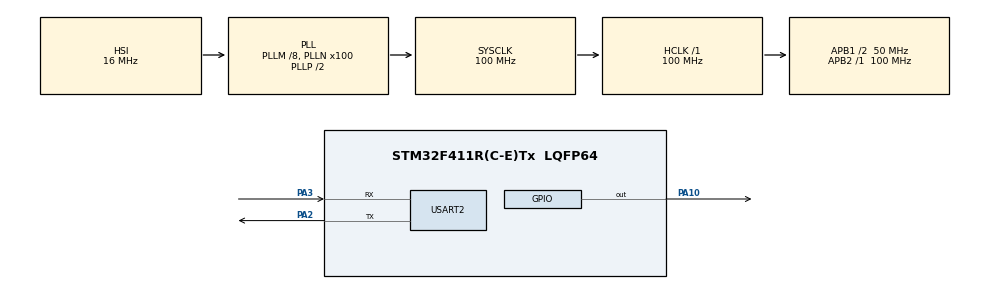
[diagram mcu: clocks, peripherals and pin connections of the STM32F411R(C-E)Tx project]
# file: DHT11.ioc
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Mcu.Family=STM32F4
Mcu.Name=STM32F411R(C-E)Tx
Mcu.Package=LQFP64
NVIC.PriorityGroup=NVIC_PRIORITYGROUP_4
PA10.Signal=GPIO_Output
PA2.Mode=Asynchronous
PA2.Signal=USART2_TX
PA3.Mode=Asynchronous
PA3.Signal=USART2_RX
ProjectManager.HeapSize=0x200
ProjectManager.StackSize=0x400
ProjectManager.TargetToolchain=STM32CubeIDE
RCC.48MHZClocksFreq_Value=50000000
RCC.AHBFreq_Value=100000000
RCC.APB1CLKDivider=RCC_HCLK_DIV2
RCC.APB1Freq_Value=50000000
RCC.APB1TimFreq_Value=100000000
RCC.APB2Freq_Value=100000000
RCC.APB2TimFreq_Value=100000000
RCC.CortexFreq_Value=100000000
RCC.HCLKFreq_Value=100000000
RCC.HSE_VALUE=25000000
RCC.HSI_VALUE=16000000
RCC.LSE_VALUE=32768
RCC.PLLM=8
RCC.PLLN=100
RCC.SYSCLKFreq_VALUE=100000000
RCC.SYSCLKSource=RCC_SYSCLKSOURCE_PLLCLK
RCC.VCOOutputFreq_Value=200000000
TIM1.Period=0xffff-1
TIM1.Prescaler=100-1
USART2.VirtualMode=VM_ASYNC
VP_TIM1_VS_ClockSourceINT.Mode=Internal
board=custom

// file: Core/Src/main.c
/* USER CODE BEGIN Header */
/**
  ******************************************************************************
  * @file           : main.c
  * @brief          : Main program body
  ******************************************************************************
  * @attention
  *
  * Copyright (c) 2023 STMicroelectronics.
  * All rights reserved.
  *
  * This software is licensed under terms that can be found in the LICENSE file
  * in the root directory of this software component.
  * If no LICENSE file comes with this software, it is provided AS-IS.
  *
  ******************************************************************************
  */
/* USER CODE END Header */
#include "main.h"
#include "tim.h"
#include "usart.h"
#include "gpio.h"

/* USER CODE BEGIN Includes */
#include "stdlib.h"
#include "string.h"
/* USER CODE END Includes */

/* USER CODE BEGIN PV */
uint8_t threshold = 50;
uint8_t RH_int;
uint8_t RH_dec;
uint8_t T_int;
uint8_t T_dec;
uint8_t checksum;
/* USER CODE END PV */

void SystemClock_Config(void);

/* USER CODE BEGIN 0 */
void HAL_DelayUs(uint16_t us)
{
	__HAL_TIM_SET_COUNTER(&htim1,0);
	while(__HAL_TIM_GET_COUNTER(&htim1) < us);
}

void HAL_Switch_Input()
{
	GPIO_InitTypeDef GPIO_InitStruct = {0};
	GPIO_InitStruct.Pin = GPIO_PIN_10;
	GPIO_InitStruct.Mode = GPIO_MODE_INPUT;
	GPIO_InitStruct.Pull = GPIO_NOPULL;
	HAL_GPIO_Init(GPIOA, &GPIO_InitStruct);
}

void HAL_Switch_Output()
{
	GPIO_InitTypeDef GPIO_InitStruct = {0};
	GPIO_InitStruct.Pin = GPIO_PIN_10;
	GPIO_InitStruct.Mode = GPIO_MODE_OUTPUT_PP;
	GPIO_InitStruct.Pull = GPIO_NOPULL;
	GPIO_InitStruct.Speed = GPIO_SPEED_FREQ_LOW;
	HAL_GPIO_Init(GPIOA, &GPIO_InitStruct);
}

void Start()
{
	HAL_Switch_Output();
	HAL_GPIO_WritePin(GPIOA, GPIO_PIN_10, GPIO_PIN_RESET);
	HAL_DelayUs(18000);
	HAL_GPIO_WritePin(GPIOA, GPIO_PIN_10, GPIO_PIN_SET);
	HAL_DelayUs(30);

	HAL_Switch_Input();
	HAL_DelayUs(40);
	while(HAL_GPIO_ReadPin(GPIOA, GPIO_PIN_10) == 0);
	while(HAL_GPIO_ReadPin(GPIOA, GPIO_PIN_10) == 1);
}

uint8_t ReadData()
{
	uint8_t res=0;
	for(uint8_t i=0; i<8; i++)
	{
	  while(HAL_GPIO_ReadPin(GPIOA, GPIO_PIN_10) == 0);
	  HAL_DelayUs(threshold);

	  if(HAL_GPIO_ReadPin(GPIOA, GPIO_PIN_10) == 1)
	  {
		  res |= 1<<(7-i);
		  while(HAL_GPIO_ReadPin(GPIOA, GPIO_PIN_10) == 1);
	  }

	}
	return res;
}

void printScreen(uint8_t T_dec, uint8_t T_int)
{
	char array_dec[4];
	char array_int[4];

	char array[25] = "Nhiet do la: ";
	itoa(T_dec, array_dec, 10);
	itoa(T_int, array_int, 10);

	strcat(array_dec, ",");
	strcat(array_dec, array_int);

	strcat(array, array_dec);
	strcat(array, " do C\n");

	HAL_UART_Transmit(&huart2, (uint8_t *) array, sizeof(array)/sizeof(array[0]), 100);
}
/* USER CODE END 0 */

int main(void)
{

  /* MCU Configuration--------------------------------------------------------*/

  /* Reset of all peripherals, Initializes the Flash interface and the Systick. */
  HAL_Init();

  /* Configure the system clock */
  SystemClock_Config();

  /* Initialize all configured peripherals */
  MX_GPIO_Init();
  MX_TIM1_Init();
  MX_USART2_UART_Init();
  /* USER CODE BEGIN 2 */
  HAL_TIM_Base_Start(&htim1);

  /* USER CODE END 2 */

  /* Infinite loop */
  /* USER CODE BEGIN WHILE */
  while (1)
  {
	  Start();

	  RH_dec = ReadData();
	  RH_int = ReadData();
	  T_dec = ReadData();
	  T_int = ReadData();
	  checksum = ReadData();

	  if(checksum == RH_int + RH_dec + T_int + T_dec)
	  {
		  printScreen(T_dec, T_int);
	  }
	  HAL_Delay(1000);

    /* USER CODE END WHILE */

  }
}

void SystemClock_Config(void)
{
  RCC_OscInitTypeDef RCC_OscInitStruct = {0};
  RCC_ClkInitTypeDef RCC_ClkInitStruct = {0};

  /** Configure the main internal regulator output voltage
  */
  __HAL_RCC_PWR_CLK_ENABLE();
  __HAL_PWR_VOLTAGESCALING_CONFIG(PWR_REGULATOR_VOLTAGE_SCALE1);

  /** Initializes the RCC Oscillators according to the specified parameters
  * in the RCC_OscInitTypeDef structure.
  */
  RCC_OscInitStruct.OscillatorType = RCC_OSCILLATORTYPE_HSI;
  RCC_OscInitStruct.HSIState = RCC_HSI_ON;
  RCC_OscInitStruct.HSICalibrationValue = RCC_HSICALIBRATION_DEFAULT;
  RCC_OscInitStruct.PLL.PLLState = RCC_PLL_ON;
  RCC_OscInitStruct.PLL.PLLSource = RCC_PLLSOURCE_HSI;
  RCC_OscInitStruct.PLL.PLLM = 8;
  RCC_OscInitStruct.PLL.PLLN = 100;
  RCC_OscInitStruct.PLL.PLLP = RCC_PLLP_DIV2;
  RCC_OscInitStruct.PLL.PLLQ = 4;
  if (HAL_RCC_OscConfig(&RCC_OscInitStruct) != HAL_OK)
  {
    Error_Handler();
  }

  /** Initializes the CPU, AHB and APB buses clocks
  */
  RCC_ClkInitStruct.ClockType = RCC_CLOCKTYPE_HCLK|RCC_CLOCKTYPE_SYSCLK
                              |RCC_CLOCKTYPE_PCLK1|RCC_CLOCKTYPE_PCLK2;
  RCC_ClkInitStruct.SYSCLKSource = RCC_SYSCLKSOURCE_PLLCLK;
  RCC_ClkInitStruct.AHBCLKDivider = RCC_SYSCLK_DIV1;
  RCC_ClkInitStruct.APB1CLKDivider = RCC_HCLK_DIV2;
  RCC_ClkInitStruct.APB2CLKDivider = RCC_HCLK_DIV1;

  if (HAL_RCC_ClockConfig(&RCC_ClkInitStruct, FLASH_LATENCY_3) != HAL_OK)
  {
    Error_Handler();
  }
}

void Error_Handler(void)
{
  __disable_irq();
  while (1)
  {
  }
}
